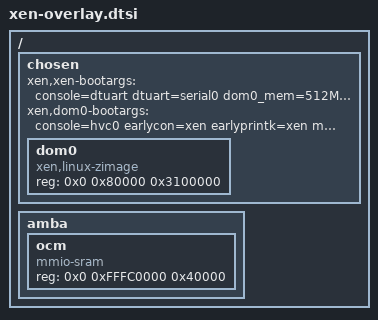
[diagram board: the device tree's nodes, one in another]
/ {
	chosen {
		#address-cells = <2>;
		#size-cells = <1>;

		xen,xen-bootargs = "console=dtuart dtuart=serial0 dom0_mem=512M bootscrub=0 maxcpus=1 timer_slop=0";
		xen,dom0-bootargs = "console=hvc0 earlycon=xen earlyprintk=xen maxcpus=1";

		dom0 {
			compatible = "xen,linux-zimage", "xen,multiboot-module";
			reg = <0x0 0x80000 0x3100000>;
		};
	};

	amba {
		ocm {
			/* TODO: Need a way to properly describe the OCM.  */
			compatible = "mmio-sram";
			reg = <0x0 0xFFFC0000 0x40000>;
		};
	};

};
